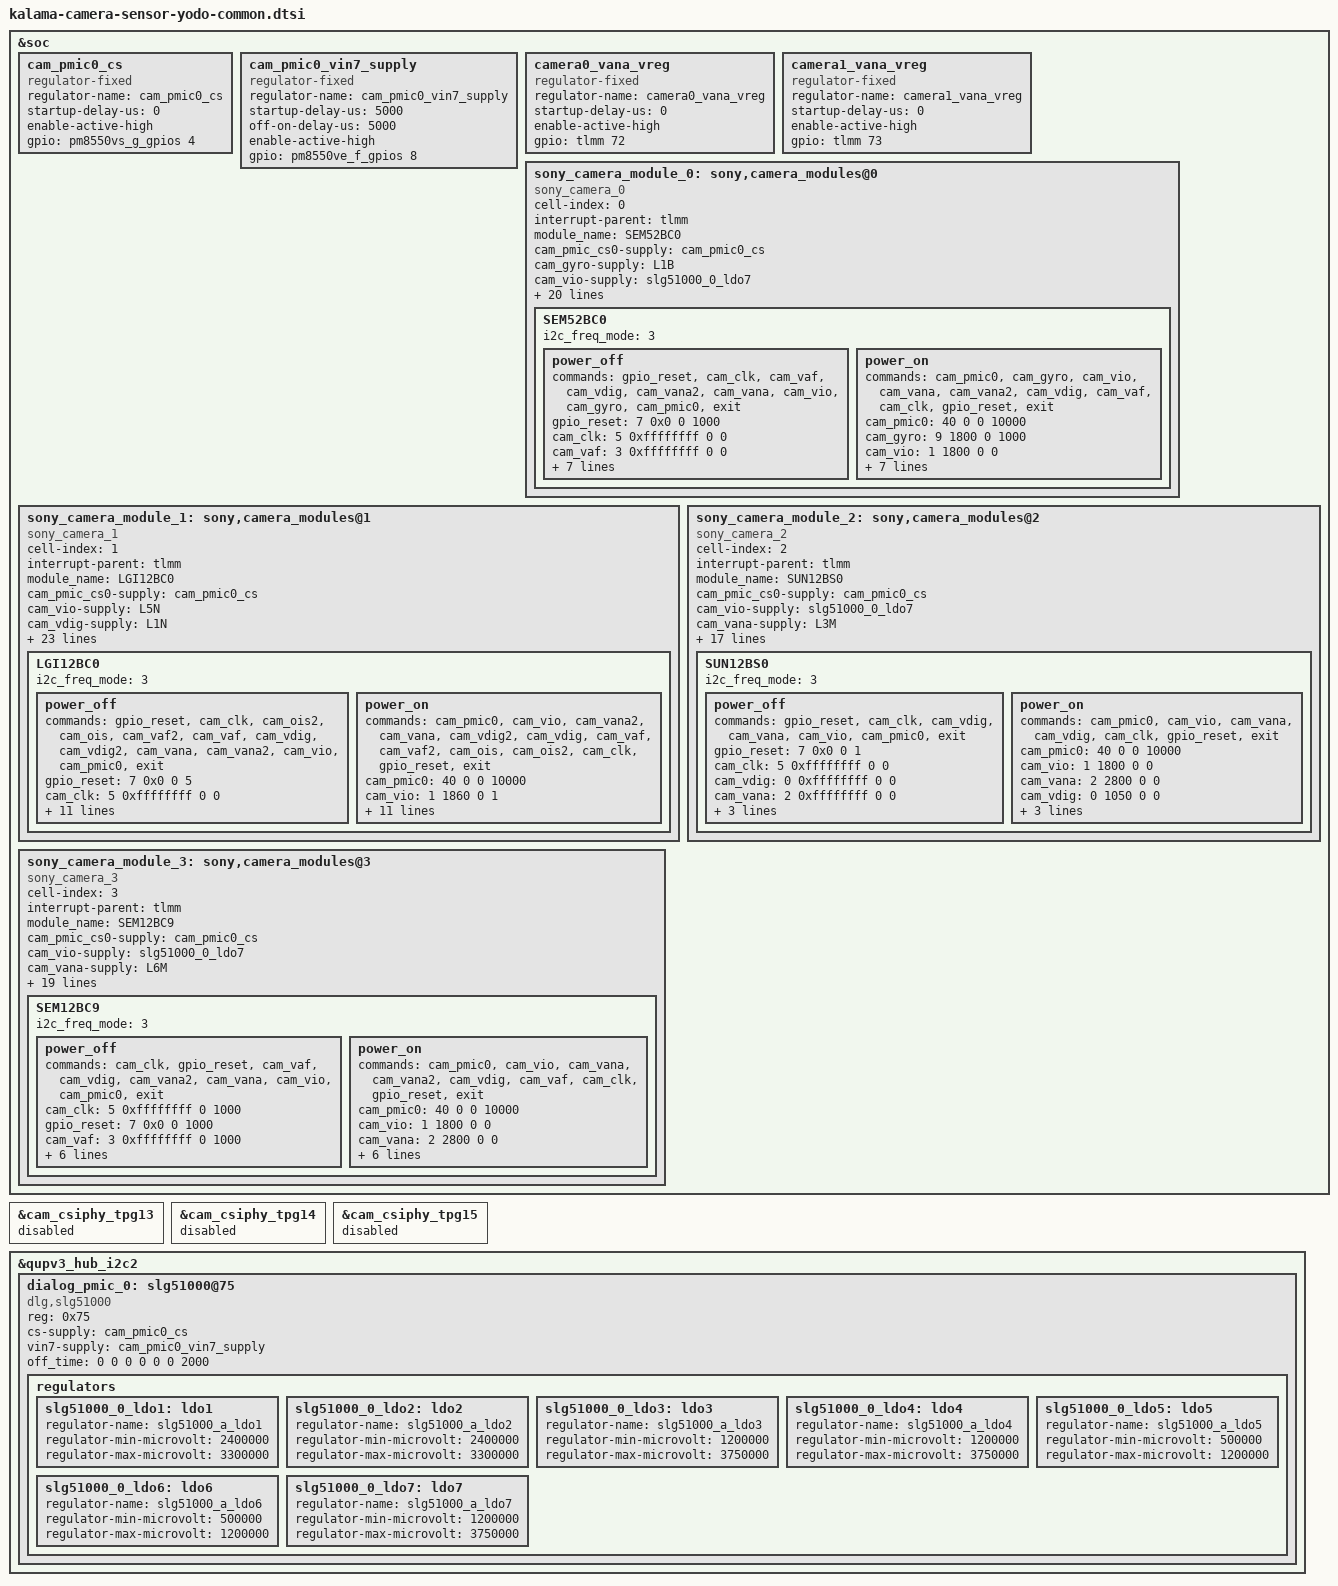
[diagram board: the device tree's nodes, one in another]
#include <dt-bindings/msm-camera.h>

&soc {
	cam_pmic0_cs: cam_pmic0_cs {
		compatible = "regulator-fixed";
		regulator-name = "cam_pmic0_cs";
		startup-delay-us = <0>;
		enable-active-high;
		gpio = <&pm8550vs_g_gpios 4 0>;
	};

	cam_pmic0_vin7_supply: cam_pmic0_vin7_supply {
		compatible = "regulator-fixed";
		regulator-name = "cam_pmic0_vin7_supply";
		startup-delay-us = <5000>;
		off-on-delay-us = <5000>;
		enable-active-high;
		gpio = <&pm8550ve_f_gpios 8 0>;
	};

	camera0_vana_vreg: camera0_vana_vreg {
		compatible = "regulator-fixed";
		regulator-name = "camera0_vana_vreg";
		startup-delay-us = <0>;
		enable-active-high;
		gpio = <&tlmm 72 0>;
	};

	camera1_vana_vreg: camera1_vana_vreg {
		compatible = "regulator-fixed";
		regulator-name = "camera1_vana_vreg";
		startup-delay-us = <0>;
		enable-active-high;
		gpio = <&tlmm 73 0>;
	};

	sony_camera_module_0: sony,camera_modules@0 {
		#address-cells = <1>;
		#size-cells = <0>;
		cell-index = <0>;
		interrupt-parent = <&tlmm>;
		status = "ok";
		compatible = "sony_camera_0";
		module_name = "SEM52BC0";
		cam_pmic_cs0-supply = <&cam_pmic0_cs>;
		cam_gyro-supply = <&L1B>;
		cam_vio-supply = <&slg51000_0_ldo7>;
		cam_vdig-supply = <&L1M>;
		cam_vana-supply = <&slg51000_0_ldo1>;
		cam_vana2-supply = <&camera0_vana_vreg>;
		cam_vaf-supply = <&L5M>;
		cam_clk-supply = <&cam_cc_titan_top_gdsc>;
		gpio-no-mux = <0>;
		pinctrl-names = "cam_default", "cam_suspend";
		pinctrl-0 = <&sm_gpio_101 &sm_gpio_117>;
		pinctrl-1 = <&sm_gpio_101 &sm_gpio_117>;
		gpios = <&tlmm 101 0>, <&tlmm 117 0>;
		gpio-req-tbl-num = <0 1>;
		gpio-req-tbl-flags = <1 0>;
		gpio-req-tbl-label = "CAMIF_MCLK1", "SONY_CAMERA_RESET";
		cci-device = <0>;
		cci-master = <1>;
		clocks = <&camcc CAM_CC_MCLK1_CLK>;
		clock-names = "cam_clk";
		clock-rates = <24000000>;
		use_spi = <0>;
		match_id = <0x34 0x0016 0x02 0x0888>;
		thremal_enable = <1>;
		SEM52BC0 {
			i2c_freq_mode = <3>;
			power_off {
				commands =
					"gpio_reset",
					"cam_clk",
					"cam_vaf",
					"cam_vdig",
					"cam_vana2",
					"cam_vana",
					"cam_vio",
					"cam_gyro",
					"cam_pmic0",
					"exit";
				gpio_reset = <7 0x0 0 1000>;
				cam_clk = <5 0xffffffff 0 0>;
				cam_vaf = <3 0xffffffff 0 0>;
				cam_vdig = <0 0xffffffff 0 0>;
				cam_vana = <2 0xffffffff 0 0>;
				cam_vana2 = <30 0xffffffff 0 5000>;
				cam_vio = <1 0xffffffff 0 0>;
				cam_gyro = <9 0xffffffff 0 0>;
				cam_pmic0 = <40 0xffffffff 0 0>;
				exit = <99 0x0 0 0>;
			};
			power_on {
				commands =
					"cam_pmic0",
					"cam_gyro",
					"cam_vio",
					"cam_vana",
					"cam_vana2",
					"cam_vdig",
					"cam_vaf",
					"cam_clk",
					"gpio_reset",
					"exit";
				cam_pmic0 = <40 0 0 10000>;
				cam_gyro = <9 1800 0 1000>;
				cam_vio = <1 1800 0 0>;
				cam_vana = <2 2800 0 0>;
				cam_vana2 = <30 0 0 5000>;
				cam_vdig = <0 870 0 0>;
				cam_vaf = <3 2900 0 1000>;
				cam_clk = <5 24000000 0 1>;
				gpio_reset = <7 1 0 1500>;
				exit = <99 0x0 0 0>;
			};
		};
	};

	sony_camera_module_1: sony,camera_modules@1 {
		#address-cells = <1>;
		#size-cells = <0>;
		cell-index = <1>;
		interrupt-parent = <&tlmm>;
		status = "ok";
		compatible = "sony_camera_1";
		module_name = "LGI12BC0";
		cam_pmic_cs0-supply = <&cam_pmic0_cs>;
		cam_vio-supply = <&L5N>;
		cam_vdig-supply = <&L1N>;
		cam_vdig2-supply = <&L2N>;
		cam_vana-supply = <&slg51000_0_ldo2>;
		cam_vana2-supply = <&camera1_vana_vreg>;
		cam_vaf-supply = <&L3N>;
		cam_vaf2-supply = <&L4N>;
		cam_ois-supply = <&L6N>;
		cam_ois2-supply = <&L7N>;
		cam_clk-supply = <&cam_cc_titan_top_gdsc>;
		gpio-no-mux = <0>;
		pinctrl-names = "cam_default", "cam_suspend";
		pinctrl-0 = <&sm_gpio_100 &sm_gpio_116>;
		pinctrl-1 = <&sm_gpio_100 &sm_gpio_116>;
		gpios = <&tlmm 100 0>, <&tlmm 116 0>;
		gpio-req-tbl-num = <0 1>;
		gpio-req-tbl-flags = <1 0>;
		gpio-req-tbl-label = "CAMIF_MCLK0", "SONY_CAMERA_RESET";
		cci-device = <0>;
		cci-master = <0>;
		clocks = <&camcc CAM_CC_MCLK0_CLK>;
		clock-names = "cam_clk";
		clock-rates = <24000000>;
		use_spi = <0>;
		match_id = <0x40 0x0000 0x02 0x0650>;
		thremal_enable = <1>;

		LGI12BC0 {
			i2c_freq_mode = <3>;
			power_off {
				commands =
					"gpio_reset",
					"cam_clk",
					"cam_ois2",
					"cam_ois",
					"cam_vaf2",
					"cam_vaf",
					"cam_vdig",
					"cam_vdig2",
					"cam_vana",
					"cam_vana2",
					"cam_vio",
					"cam_pmic0",
					"exit";
				gpio_reset = <7 0x0 0 5>;
				cam_clk = <5 0xffffffff 0 0>;
				cam_ois2 = <12 0xffffffff 0 1000>;
				cam_ois = <11 0xffffffff 0 0>;
				cam_vaf2 = <4 0xffffffff 0 1000>;
				cam_vaf = <3 0xffffffff 0 0>;
				cam_vdig2 = <20 0xffffffff 0 0>;
				cam_vdig = <0 0xffffffff 0 0>;
				cam_vana2 = <30 0xffffffff 0 5000>;
				cam_vana = <2 0xffffffff 0 0>;
				cam_vio = <1 0xffffffff 0 1000>;
				cam_pmic0 = <40 0xffffffff 0 0>;
				exit = <99 0x0 0 0>;
			};
			power_on {
				commands =
					"cam_pmic0",
					"cam_vio",
					"cam_vana2",
					"cam_vana",
					"cam_vdig2",
					"cam_vdig",
					"cam_vaf",
					"cam_vaf2",
					"cam_ois",
					"cam_ois2",
					"cam_clk",
					"gpio_reset",
					"exit";
				cam_pmic0 = <40 0 0 10000>;
				cam_vio = <1 1860 0 1>;
				cam_vana2 = <30 0 0 5000>;
				cam_vana = <2 2800 0 1>;
				cam_vdig2 = <20 900 0 1>;
				cam_vdig = <0 810 0 1>;
				cam_vaf = <3 2800 0 0>;
				cam_vaf2 = <4 2800 0 0>;
				cam_ois = <11 2800 0 0>;
				cam_ois2 = <12 2800 0 0>;
				cam_clk = <5 24000000 0 1>;
				gpio_reset = <7 1 0 1100>;
				exit = <99 0x0 0 0>;
			};
		};
	};

	sony_camera_module_2: sony,camera_modules@2 {
		#address-cells = <1>;
		#size-cells = <0>;
		cell-index = <2>;
		interrupt-parent = <&tlmm>;
		status = "ok";
		compatible = "sony_camera_2";
		module_name = "SUN12BS0";
		cam_pmic_cs0-supply = <&cam_pmic0_cs>;
		cam_vio-supply = <&slg51000_0_ldo7>;
		cam_vana-supply = <&L3M>;
		cam_vdig-supply = <&L2M>;
		cam_clk-supply = <&cam_cc_titan_top_gdsc>;
		gpio-no-mux = <0>;
		pinctrl-names = "cam_default", "cam_suspend";
		pinctrl-0 = <&sm_gpio_103 &sm_gpio_119>;
		pinctrl-1 = <&sm_gpio_103 &sm_gpio_119>;
		gpios = <&tlmm 103 0>, <&tlmm 119 0>;
		gpio-req-tbl-num = <0 1>;
		gpio-req-tbl-flags = <1 0>;
		gpio-req-tbl-label = "CAMIF_MCLK3", "SONY_CAMERA_RESET";
		cci-device = <1>;
		cci-master = <1>;
		clocks = <&camcc CAM_CC_MCLK3_CLK>;
		clock-names = "cam_clk";
		use_spi = <0>;
		clock-rates = <24000000>;
		match_id = <0x20 0x0016 0x02 0x0663>;
		thremal_enable = <1>;
		SUN12BS0 {
			i2c_freq_mode = <3>;
			power_off {
				commands =
					"gpio_reset",
					"cam_clk",
					"cam_vdig",
					"cam_vana",
					"cam_vio",
					"cam_pmic0",
					"exit";
				gpio_reset = <7 0x0 0 1>;
				cam_clk = <5 0xffffffff 0 0>;
				cam_vdig = <0 0xffffffff 0 0>;
				cam_vana = <2 0xffffffff 0 0>;
				cam_vio = <1 0xffffffff 0 0>;
				cam_pmic0 = <40 0xffffffff 0 0>;
				exit = <99 0x0 0 0>;
			};
			power_on {
				commands =
					"cam_pmic0",
					"cam_vio",
					"cam_vana",
					"cam_vdig",
					"cam_clk",
					"gpio_reset",
					"exit";
				cam_pmic0 = <40 0 0 10000>;
				cam_vio = <1 1800 0 0>;
				cam_vana = <2 2800 0 0>;
				cam_vdig = <0 1050 0 0>;
				cam_clk = <5 24000000 0 1>;
				gpio_reset = <7 1 0 1000>;
				exit = <99 0x0 0 0>;
			};
		};
	};

	sony_camera_module_3: sony,camera_modules@3 {
		#address-cells = <1>;
		#size-cells = <0>;
		cell-index = <3>;
		interrupt-parent = <&tlmm>;
		status = "ok";
		compatible = "sony_camera_3";
		module_name = "SEM12BC9";
		cam_pmic_cs0-supply = <&cam_pmic0_cs>;
		cam_vio-supply = <&slg51000_0_ldo7>;
		cam_vana-supply = <&L6M>;
		cam_vana2-supply = <&L7M>;
		cam_vdig-supply = <&slg51000_0_ldo6>;
		cam_vaf-supply = <&slg51000_0_ldo4>;
		cam_clk-supply = <&cam_cc_titan_top_gdsc>;
		gpio-no-mux = <0>;
		pinctrl-names = "cam_default", "cam_suspend";
		pinctrl-0 = <&sm_gpio_102 &sm_gpio_118>;
		pinctrl-1 = <&sm_gpio_102 &sm_gpio_118>;
		gpios = <&tlmm 102 0>, <&tlmm 118 0>;
		gpio-req-tbl-num = <0 1>;
		gpio-req-tbl-flags = <1 0>;
		gpio-req-tbl-label = "CAMIF_MCLK2", "SONY_CAMERA_RESET";
		cci-device = <1>;
		cci-master = <0>;
		clocks = <&camcc CAM_CC_MCLK2_CLK>;
		clock-names = "cam_clk";
		use_spi = <0>;
		clock-rates = <24000000>;
		match_id = <0x20 0x0016 0x02 0x0563>;
		thremal_enable = <1>;
		SEM12BC9 {
			i2c_freq_mode = <3>;
			power_off {
				commands =
					"cam_clk",
					"gpio_reset",
					"cam_vaf",
					"cam_vdig",
					"cam_vana2",
					"cam_vana",
					"cam_vio",
					"cam_pmic0",
					"exit";
				cam_clk = <5 0xffffffff 0 1000>;
				gpio_reset = <7 0x0 0 1000>;
				cam_vaf = <3 0xffffffff 0 1000>;
				cam_vdig = <0 0xffffffff 0 1000>;
				cam_vana2 = <30 0xffffffff 0 1000>;
				cam_vana = <2 0xffffffff 0 1000>;
				cam_vio = <1 0xffffffff 0 0>;
				cam_pmic0 = <40 0xffffffff 0 0>;
				exit = <99 0x0 0 0>;
			};
			power_on {
				commands =
					"cam_pmic0",
					"cam_vio",
					"cam_vana",
					"cam_vana2",
					"cam_vdig",
					"cam_vaf",
					"cam_clk",
					"gpio_reset",
					"exit";
				cam_pmic0 = <40 0 0 10000>;
				cam_vio = <1 1800 0 0>;
				cam_vana = <2 2800 0 0>;
				cam_vana2 = <30 1800 0 0>;
				cam_vdig = <0 1100 0 0>;
				cam_vaf = <3 2800 0 0>;
				cam_clk = <5 24000000 0 1>;
				gpio_reset = <7 1 0 1000>;
				exit = <99 0x0 0 0>;
			};
		};
	};
};

&cam_csiphy_tpg13 {
	status = "disabled";
};

&cam_csiphy_tpg14 {
	status = "disabled";
};

&cam_csiphy_tpg15 {
	status = "disabled";
};

&qupv3_hub_i2c2 {
	dialog_pmic_0:slg51000@75 {
		compatible = "dlg,slg51000";
		reg = <0x75>;
		cs-supply = <&cam_pmic0_cs>;
		vin7-supply = <&cam_pmic0_vin7_supply>;
		off_time = <0 0 0 0 0 0 2000>;
		status = "ok";

		regulators {
			slg51000_0_ldo1: ldo1 {
				regulator-name = "slg51000_a_ldo1";
				regulator-min-microvolt = <2400000>;
				regulator-max-microvolt = <3300000>;
			};

			slg51000_0_ldo2: ldo2 {
				regulator-name = "slg51000_a_ldo2";
				regulator-min-microvolt = <2400000>;
				regulator-max-microvolt = <3300000>;
			};

			slg51000_0_ldo3: ldo3 {
				regulator-name = "slg51000_a_ldo3";
				regulator-min-microvolt = <1200000>;
				regulator-max-microvolt = <3750000>;
			};

			slg51000_0_ldo4: ldo4 {
				regulator-name = "slg51000_a_ldo4";
				regulator-min-microvolt = <1200000>;
				regulator-max-microvolt = <3750000>;
			};

			slg51000_0_ldo5: ldo5 {
				regulator-name = "slg51000_a_ldo5";
				regulator-min-microvolt = <500000>;
				regulator-max-microvolt = <1200000>;
			};

			slg51000_0_ldo6: ldo6 {
				regulator-name = "slg51000_a_ldo6";
				regulator-min-microvolt = <500000>;
				regulator-max-microvolt = <1200000>;
			};

			slg51000_0_ldo7: ldo7 {
				regulator-name = "slg51000_a_ldo7";
				regulator-min-microvolt = <1200000>;
				regulator-max-microvolt = <3750000>;
			};
		};
	};
};

